AUTOSAR XML (schema 00044)
package /ComponentTypes
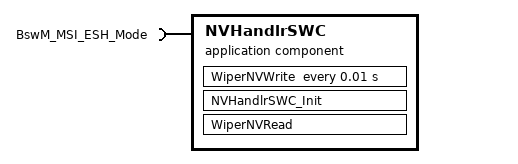
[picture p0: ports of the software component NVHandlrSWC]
  application sw component type NVHandlrSWC
    provide/require port SCMWiperDE00ConfigsNv: nv-provide-com-spec=FrontWashWipe, nv-require-com-spec=FrontWashWipe, provided-required-interface=SCMWiperDE00ConfigsNv
    provide/require port WiperStalkPushPullStuckStatusNv: nv-provide-com-spec=RdStuckStatus, nv-require-com-spec=RdStuckStatus, provided-required-interface=WiperStalkPushPullStuckStatusNv
    require port BswM_MSI_ESH_Mode: mode-switch-receiver-com-spec=BswM_MDGP_ESH_Mode, required-interface=BswM_MSI_ESH_Mode
    10 x provide/require port:
      SCMWiperDE00Configs: nonqueued-sender-com-spec{data-element=FrontWashWipe, init-value=0}, nonqueued-receiver-com-spec{data-element=FrontWashWipe, filter=data-filter-type=ALWAYS}, provided-required-interface=SCMWiperDE00Configs
      WiperStalkPushPullStuckStatus: nonqueued-sender-com-spec{data-element=RdStuckStatus, init-value=0}, nonqueued-receiver-com-spec{data-element=RdStuckStatus, filter=data-filter-type=ALWAYS}, provided-required-interface=WiperStalkPushPullStuckStatus
      TeleFrwrdStuckSw: nonqueued-sender-com-spec{data-element=TeleFrwrdSw, init-value=0}, nonqueued-receiver-com-spec{data-element=TeleFrwrdSw, filter=data-filter-type=ALWAYS}, provided-required-interface=TeleFrwrdStuckSw
      TeleFrwrdStuckSwNv: nv-provide-com-spec=TeleFrwrdSw, nv-require-com-spec=TeleFrwrdSw, provided-required-interface=TeleFrwrdStuckSwNv
      TeleRrwrdStuckSw: nonqueued-sender-com-spec{data-element=TeleRrwrdSw, init-value=0}, nonqueued-receiver-com-spec{data-element=TeleRrwrdSw, filter=data-filter-type=ALWAYS}, provided-required-interface=TeleRrwrdStuckSw
      TeleRrwrdStuckSwNv: nv-provide-com-spec=TeleRrwrdSw, nv-require-com-spec=TeleRrwrdSw, provided-required-interface=TeleRrwrdStuckSwNv
      TiltDownStuckSw: nonqueued-sender-com-spec{data-element=TiltDownStuckSw, init-value=0}, nonqueued-receiver-com-spec{data-element=TiltDownStuckSw, filter=data-filter-type=ALWAYS}, provided-required-interface=TiltDownStuckSw
      TiltDownStuckSwNv: nv-provide-com-spec=TiltDownStuckSw, nv-require-com-spec=TiltDownStuckSw, provided-required-interface=TiltDownStuckSwNv
      TiltUpStuckSw: nonqueued-sender-com-spec{data-element=TiltUpStuckSw, init-value=0}, nonqueued-receiver-com-spec{data-element=TiltUpStuckSw, filter=data-filter-type=ALWAYS}, provided-required-interface=TiltUpStuckSw
      TiltUpStuckSwNv: nv-provide-com-spec=TiltUpStuckSw, nv-require-com-spec=TiltUpStuckSw, provided-required-interface=TiltUpStuckSwNv
    behavior NVHandlrSWC_InternalBehavior
      init event NVHandlrSWC_InitEvent: start-on-event=NVHandlrSWC_Init
      swc mode switch event MST_WiperNVRead_3: start-on-event=WiperNVRead, activation=ON-ENTRY, mode=BswM_MSI_ESH_Mode.BswM_MDGP_ESH_Mode.RUN
      timing event TMT_WiperNVWrite: start-on-event=WiperNVWrite, period=0.01
      runnable NVHandlrSWC_Init
      runnable WiperNVRead
        data-receive-point-by-arguments:
          6 x access:
            REC_WiperStalkPushPullStuckStatusReadNv_RdStuckStatus: accessed-variable=WiperStalkPushPullStuckStatusNv.RdStuckStatus
            REC_SCMWiperDE00NVConfigsNv_FrontWashWipe: accessed-variable=SCMWiperDE00ConfigsNv.FrontWashWipe
            REC_TeleFrwrdStuckSwNv_TeleFrwrdSw: accessed-variable=TeleFrwrdStuckSwNv.TeleFrwrdSw
            REC_TeleRrwrdStuckSwNv_TeleRrwrdSw: accessed-variable=TeleRrwrdStuckSwNv.TeleRrwrdSw
            REC_TiltDownStuckSwNv_TiltDownStuckSw: accessed-variable=TiltDownStuckSwNv.TiltDownStuckSw
            REC_TiltUpStuckSwNv_TiltUpStuckSw: accessed-variable=TiltUpStuckSwNv.TiltUpStuckSw
        data-send-points:
          6 x access:
            SEND_SCMWiperDE00Configs_FrontWashWipe: accessed-variable=SCMWiperDE00Configs.FrontWashWipe
            SEND_WiperStalkPushPullStuckStatus_RdStuckStatus: accessed-variable=WiperStalkPushPullStuckStatus.RdStuckStatus
            SEND_TeleFrwrdStuckSw_TeleFrwrdSw: accessed-variable=TeleFrwrdStuckSw.TeleFrwrdSw
            SEND_TeleRrwrdStuckSw_TeleRrwrdSw: accessed-variable=TeleRrwrdStuckSw.TeleRrwrdSw
            SEND_TiltDownStuckSw_TiltDownStuckSw: accessed-variable=TiltDownStuckSw.TiltDownStuckSw
            SEND_TiltUpStuckSw_TiltUpStuckSw: accessed-variable=TiltUpStuckSw.TiltUpStuckSw
      runnable WiperNVWrite: mode-access-point=BswM_MSI_ESH_Mode.BswM_MDGP_ESH_Mode
        data-receive-point-by-arguments:
          6 x access:
            REC_SCMWiperDE00Configs_FrontWashWipe: accessed-variable=SCMWiperDE00Configs.FrontWashWipe
            REC_WiperStalkPushPullStuckStatus_RdStuckStatus: accessed-variable=WiperStalkPushPullStuckStatus.RdStuckStatus
            REC_TeleFrwrdStuckSw_TeleFrwrdSw: accessed-variable=TeleFrwrdStuckSw.TeleFrwrdSw
            REC_TeleRrwrdStuckSw_TeleRrwrdSw: accessed-variable=TeleRrwrdStuckSw.TeleRrwrdSw
            REC_TiltDownStuckSw_TiltDownStuckSw: accessed-variable=TiltDownStuckSw.TiltDownStuckSw
            REC_TiltUpStuckSw_TiltUpStuckSw: accessed-variable=TiltUpStuckSw.TiltUpStuckSw
        data-send-points:
          6 x access:
            SEND_SCMWiperDE00ConfigsNv_FrontWashWipe: accessed-variable=SCMWiperDE00ConfigsNv.FrontWashWipe
            SEND_WiperStalkPushPullStuckStatusNv_RdStuckStatus: accessed-variable=WiperStalkPushPullStuckStatusNv.RdStuckStatus
            SEND_TeleFrwrdStuckSwNv_TeleFrwrdSw: accessed-variable=TeleFrwrdStuckSwNv.TeleFrwrdSw
            SEND_TeleRrwrdStuckSwNv_TeleRrwrdSw: accessed-variable=TeleRrwrdStuckSwNv.TeleRrwrdSw
            SEND_TiltDownStuckSwNv_TiltDownStuckSw: accessed-variable=TiltDownStuckSwNv.TiltDownStuckSw
            SEND_TiltUpStuckSwNv_TiltUpStuckSw: accessed-variable=TiltUpStuckSwNv.TiltUpStuckSw
  swc implementation NVHandlrSWC_Implementation: behavior=NVHandlrSWC_InternalBehavior
    code-descriptors:
      code Default: artifact-descriptors=autosar-engineering-object=category=SWSRC
